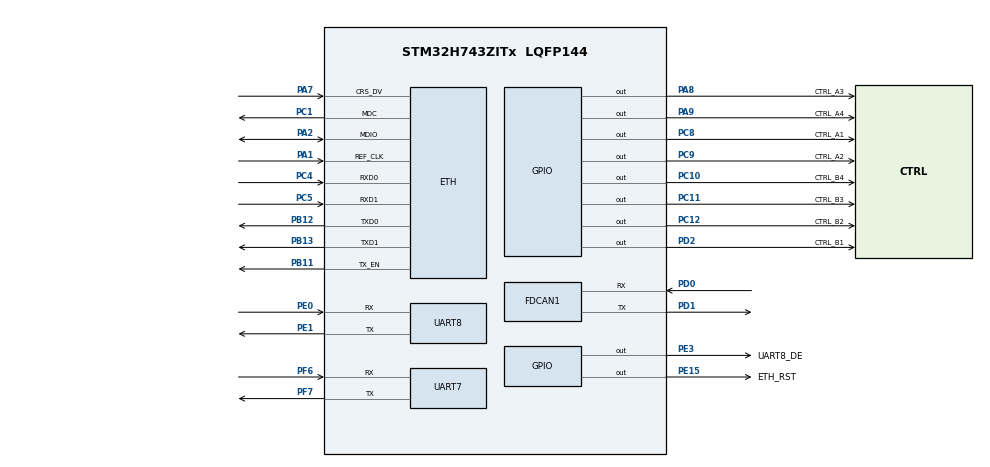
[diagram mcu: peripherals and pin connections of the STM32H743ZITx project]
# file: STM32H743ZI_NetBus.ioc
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CORTEX_M7.AccessPermission_S-Cortex_Memory_Protection_Unit_Region1_Settings_S=MPU_REGION_FULL_ACCESS
CORTEX_M7.AccessPermission_Spec=MPU_REGION_FULL_ACCESS
CORTEX_M7.BaseAddress_S-Cortex_Memory_Protection_Unit_Region1_Settings_S=0x30044000
CORTEX_M7.BaseAddress_Spec=0x30040000
CORTEX_M7.CPU_DCache=Enabled
CORTEX_M7.CPU_ICache=Enabled
CORTEX_M7.DisableExec_Spec=MPU_INSTRUCTION_ACCESS_ENABLE
CORTEX_M7.Enable_S-Cortex_Memory_Protection_Unit_Region1_Settings_S=MPU_REGION_ENABLE
CORTEX_M7.IsBufferable_Spec=MPU_ACCESS_BUFFERABLE
CORTEX_M7.IsCacheable_S-Cortex_Memory_Protection_Unit_Region1_Settings_S=MPU_ACCESS_CACHEABLE
CORTEX_M7.IsShareable_Spec=MPU_ACCESS_NOT_SHAREABLE
CORTEX_M7.Size_S-Cortex_Memory_Protection_Unit_Region1_Settings_S=MPU_REGION_SIZE_16KB
CORTEX_M7.Size_Spec=MPU_REGION_SIZE_256B
CORTEX_M7.SubRegionDisable_Spec=0x00
CORTEX_M7.default_mode_Activation=1
Dma.Request0=UART7_RX
Dma.Request1=UART7_TX
Dma.Request2=UART8_RX
Dma.Request3=UART8_TX
Dma.UART7_RX.0.Direction=DMA_PERIPH_TO_MEMORY
Dma.UART7_RX.0.EventEnable=DISABLE
Dma.UART7_RX.0.FIFOMode=DMA_FIFOMODE_DISABLE
Dma.UART7_RX.0.Instance=DMA1_Stream0
Dma.UART7_RX.0.MemDataAlignment=DMA_MDATAALIGN_BYTE
Dma.UART7_RX.0.MemInc=DMA_MINC_ENABLE
Dma.UART7_RX.0.Mode=DMA_CIRCULAR
Dma.UART7_RX.0.PeriphDataAlignment=DMA_PDATAALIGN_BYTE
Dma.UART7_RX.0.PeriphInc=DMA_PINC_DISABLE
Dma.UART7_RX.0.Polarity=HAL_DMAMUX_REQ_GEN_RISING
Dma.UART7_RX.0.Priority=DMA_PRIORITY_MEDIUM
Dma.UART7_RX.0.RequestNumber=1
Dma.UART7_RX.0.SignalID=NONE
Dma.UART7_RX.0.SyncEnable=DISABLE
Dma.UART7_RX.0.SyncPolarity=HAL_DMAMUX_SYNC_NO_EVENT
Dma.UART7_RX.0.SyncRequestNumber=1
Dma.UART7_RX.0.SyncSignalID=NONE
Dma.UART7_TX.1.Direction=DMA_MEMORY_TO_PERIPH
Dma.UART7_TX.1.EventEnable=DISABLE
Dma.UART7_TX.1.FIFOMode=DMA_FIFOMODE_DISABLE
Dma.UART7_TX.1.Instance=DMA1_Stream1
Dma.UART7_TX.1.MemDataAlignment=DMA_MDATAALIGN_BYTE
Dma.UART7_TX.1.MemInc=DMA_MINC_ENABLE
Dma.UART7_TX.1.Mode=DMA_NORMAL
Dma.UART7_TX.1.PeriphDataAlignment=DMA_PDATAALIGN_BYTE
Dma.UART7_TX.1.PeriphInc=DMA_PINC_DISABLE
Dma.UART7_TX.1.Polarity=HAL_DMAMUX_REQ_GEN_RISING
Dma.UART7_TX.1.Priority=DMA_PRIORITY_LOW
Dma.UART7_TX.1.RequestNumber=1
Dma.UART7_TX.1.SignalID=NONE
Dma.UART7_TX.1.SyncEnable=DISABLE
Dma.UART7_TX.1.SyncPolarity=HAL_DMAMUX_SYNC_NO_EVENT
Dma.UART7_TX.1.SyncRequestNumber=1
Dma.UART7_TX.1.SyncSignalID=NONE
Dma.UART8_RX.2.Direction=DMA_PERIPH_TO_MEMORY
Dma.UART8_RX.2.EventEnable=DISABLE
Dma.UART8_RX.2.FIFOMode=DMA_FIFOMODE_DISABLE
Dma.UART8_RX.2.Instance=DMA1_Stream2
Dma.UART8_RX.2.MemDataAlignment=DMA_MDATAALIGN_BYTE
Dma.UART8_RX.2.MemInc=DMA_MINC_ENABLE
Dma.UART8_RX.2.Mode=DMA_CIRCULAR
Dma.UART8_RX.2.PeriphDataAlignment=DMA_PDATAALIGN_BYTE
Dma.UART8_RX.2.PeriphInc=DMA_PINC_DISABLE
Dma.UART8_RX.2.Polarity=HAL_DMAMUX_REQ_GEN_RISING
Dma.UART8_RX.2.Priority=DMA_PRIORITY_HIGH
Dma.UART8_RX.2.RequestNumber=1
Dma.UART8_RX.2.SignalID=NONE
Dma.UART8_RX.2.SyncEnable=DISABLE
Dma.UART8_RX.2.SyncPolarity=HAL_DMAMUX_SYNC_NO_EVENT
Dma.UART8_RX.2.SyncRequestNumber=1
Dma.UART8_RX.2.SyncSignalID=NONE
Dma.UART8_TX.3.Direction=DMA_MEMORY_TO_PERIPH
Dma.UART8_TX.3.EventEnable=DISABLE
Dma.UART8_TX.3.FIFOMode=DMA_FIFOMODE_DISABLE
Dma.UART8_TX.3.Instance=DMA1_Stream3
Dma.UART8_TX.3.MemDataAlignment=DMA_MDATAALIGN_BYTE
Dma.UART8_TX.3.MemInc=DMA_MINC_ENABLE
Dma.UART8_TX.3.Mode=DMA_NORMAL
Dma.UART8_TX.3.PeriphDataAlignment=DMA_PDATAALIGN_BYTE
Dma.UART8_TX.3.PeriphInc=DMA_PINC_DISABLE
Dma.UART8_TX.3.Polarity=HAL_DMAMUX_REQ_GEN_RISING
Dma.UART8_TX.3.Priority=DMA_PRIORITY_MEDIUM
Dma.UART8_TX.3.RequestNumber=1
Dma.UART8_TX.3.SignalID=NONE
Dma.UART8_TX.3.SyncEnable=DISABLE
Dma.UART8_TX.3.SyncPolarity=HAL_DMAMUX_SYNC_NO_EVENT
Dma.UART8_TX.3.SyncRequestNumber=1
Dma.UART8_TX.3.SyncSignalID=NONE
ETH.MediaInterface=HAL_ETH_RMII_MODE
ETH.RxBuffLen=1528
ETH.RxBufferAddress=0x30040200
ETH.RxDescAddress=0x30040000
ETH.TxDescAddress=0x30040060
FDCAN1.AutoRetransmission=ENABLE
FDCAN1.CalculateBaudRateNominal=1000000
FDCAN1.CalculateTimeBitNominal=1000
FDCAN1.CalculateTimeQuantumNominal=15.625
FDCAN1.DataTimeSeg1=23
FDCAN1.ExtFiltersNbr=4
FDCAN1.FrameFormat=FDCAN_FRAME_FD_BRS
FDCAN1.NominalPrescaler=1
FDCAN1.NominalSyncJumpWidth=16
FDCAN1.NominalTimeSeg1=47
FDCAN1.NominalTimeSeg2=16
FDCAN1.RxBufferSize=FDCAN_DATA_BYTES_64
FDCAN1.RxBuffersNbr=2
FDCAN1.RxFifo0ElmtSize=FDCAN_DATA_BYTES_64
FDCAN1.RxFifo0ElmtsNbr=8
FDCAN1.RxFifo1ElmtSize=FDCAN_DATA_BYTES_64
FDCAN1.RxFifo1ElmtsNbr=8
FDCAN1.StdFiltersNbr=4
FDCAN1.TxBuffersNbr=8
FDCAN1.TxElmtSize=FDCAN_DATA_BYTES_64
FDCAN1.TxEventsNbr=8
FDCAN1.TxFifoQueueElmtsNbr=8
FREERTOS.Mutexes01=SCPI_Mutex,Dynamic,NULL,Available;Modbus_Mutex,Dynamic,NULL,Available
FREERTOS.Tasks01=defaultTask,24,512,StartDefaultTask,As weak,NULL,Dynamic,NULL,NULL;ETH_Task,24,4096,StartETHTask,As weak,NULL,Dynamic,NULL,NULL;Modbus_Task,8,512,StartModbusTask,As weak,NULL,Dynamic,NULL,NULL;Can_Task,8,512,StartCanTask,As weak,NULL,Dynamic,NULL,NULL;SCPI_Task,8,1024,StartSCPITask,As weak,NULL,Dynamic,NULL,NULL
FREERTOS.configMINIMAL_STACK_SIZE=256
FREERTOS.configTOTAL_HEAP_SIZE=40960
FREERTOS.configUSE_NEWLIB_REENTRANT=1
LWIP.BSP.number=1
LWIP.GATEWAY_ADDRESS=192.168.001.001
LWIP.HTTPD_USE_CUSTOM_FSDATA=1
LWIP.IP_ADDRESS=192.168.001.010
LWIP.LWIP_DHCP=0
LWIP.LWIP_HTTPD=1
LWIP.LWIP_NETIF_STATUS_CALLBACK=1
LWIP.LWIP_RAM_HEAP_POINTER=0x30044000
LWIP.MEMP_MEM_MALLOC=1
LWIP.MEM_SIZE=14336
LWIP.NETMASK_ADDRESS=255.255.255.000
LWIP.TCPIP_THREAD_PRIO=25
LWIP.Version=v2.2.1_Cube
LWIP0.BSP.STBoard=false
LWIP0.BSP.api=BSP_COMPONENT_DRIVER
LWIP0.BSP.component=LAN8742
LWIP0.BSP.instance=LAN8742
LWIP0.BSP.name=Driver_PHY
LWIP0.BSP.semaphore=S_LAN8742
LWIP0.BSP.solution=LAN8742
Mcu.Family=STM32H7
Mcu.Name=STM32H743ZITx
Mcu.Package=LQFP144
NVIC.DMA1_Stream0_IRQn=true\:8\:0\:true\:false\:true\:true\:false\:true\:true
NVIC.DMA1_Stream1_IRQn=true\:9\:0\:true\:false\:true\:true\:false\:true\:true
NVIC.DMA1_Stream2_IRQn=true\:9\:0\:true\:false\:true\:true\:false\:true\:true
NVIC.DMA1_Stream3_IRQn=true\:10\:0\:true\:false\:true\:true\:false\:true\:true
NVIC.ETH_IRQn=true\:6\:0\:true\:false\:true\:true\:true\:true\:true
NVIC.ETH_WKUP_IRQn=true\:6\:0\:true\:false\:true\:true\:true\:true\:true
NVIC.FDCAN1_IT0_IRQn=true\:7\:0\:true\:false\:true\:true\:true\:true\:true
NVIC.FDCAN1_IT1_IRQn=true\:7\:0\:true\:false\:true\:true\:true\:true\:true
NVIC.PriorityGroup=NVIC_PRIORITYGROUP_4
NVIC.TIM1_UP_IRQn=true\:15\:0\:false\:false\:true\:false\:false\:true\:true
NVIC.TimeBase=TIM1_UP_IRQn
NVIC.TimeBaseIP=TIM1
NVIC.UART7_IRQn=true\:9\:0\:true\:false\:true\:true\:true\:true\:true
NVIC.UART8_IRQn=true\:8\:0\:true\:false\:true\:true\:true\:true\:true
PA1.GPIO_Speed_Default_HIGH=GPIO_SPEED_FREQ_VERY_HIGH
PA1.Mode=RMII
PA1.Signal=ETH_REF_CLK
PA13\ (JTMS/SWDIO).Mode=Serial_Wire
PA13\ (JTMS/SWDIO).Signal=DEBUG_JTMS-SWDIO
PA14\ (JTCK/SWCLK).Mode=Serial_Wire
PA14\ (JTCK/SWCLK).Signal=DEBUG_JTCK-SWCLK
PA2.GPIO_Speed_Default_HIGH=GPIO_SPEED_FREQ_VERY_HIGH
PA2.Mode=RMII
PA2.Signal=ETH_MDIO
PA7.GPIO_Speed_Default_HIGH=GPIO_SPEED_FREQ_VERY_HIGH
PA7.Mode=RMII
PA7.Signal=ETH_CRS_DV
PA8.GPIO_Label=CTRL_A3
PA8.Signal=GPIO_Output
PA9.GPIO_Label=CTRL_A4
PA9.Signal=GPIO_Output
PB11.GPIO_Speed_Default_HIGH=GPIO_SPEED_FREQ_VERY_HIGH
PB11.Mode=RMII
PB11.Signal=ETH_TX_EN
PB12.GPIO_Speed_Default_HIGH=GPIO_SPEED_FREQ_VERY_HIGH
PB12.Mode=RMII
PB12.Signal=ETH_TXD0
PB13.GPIO_Speed_Default_HIGH=GPIO_SPEED_FREQ_VERY_HIGH
PB13.Mode=RMII
PB13.Signal=ETH_TXD1
PC1.GPIO_Speed_Default_HIGH=GPIO_SPEED_FREQ_VERY_HIGH
PC1.Mode=RMII
PC1.Signal=ETH_MDC
PC10.GPIO_Label=CTRL_B4
PC10.Signal=GPIO_Output
PC11.GPIO_Label=CTRL_B3
PC11.Signal=GPIO_Output
PC12.GPIO_Label=CTRL_B2
PC12.Signal=GPIO_Output
PC4.GPIO_Speed_Default_HIGH=GPIO_SPEED_FREQ_VERY_HIGH
PC4.Mode=RMII
PC4.Signal=ETH_RXD0
PC5.GPIO_Speed_Default_HIGH=GPIO_SPEED_FREQ_VERY_HIGH
PC5.Mode=RMII
PC5.Signal=ETH_RXD1
PC8.GPIO_Label=CTRL_A1
PC8.Signal=GPIO_Output
PC9.GPIO_Label=CTRL_A2
PC9.Signal=GPIO_Output
PD0.Mode=FDCAN_Activate
PD0.Signal=FDCAN1_RX
PD1.Mode=FDCAN_Activate
PD1.Signal=FDCAN1_TX
PD2.GPIO_Label=CTRL_B1
PD2.Signal=GPIO_Output
PE0.Mode=Asynchronous
PE0.Signal=UART8_RX
PE1.Mode=Asynchronous
PE1.Signal=UART8_TX
PE15.GPIO_Label=ETH_RST
PE15.PinState=GPIO_PIN_SET
PE15.Signal=GPIO_Output
PE3.GPIO_Label=UART8_DE
PE3.Signal=GPIO_Output
PF6.Mode=Asynchronous
PF6.Signal=UART7_RX
PF7.Mode=Asynchronous
PF7.Signal=UART7_TX
PH0-OSC_IN\ (PH0).Mode=HSE-External-Oscillator
PH0-OSC_IN\ (PH0).Signal=RCC_OSC_IN
PH1-OSC_OUT\ (PH1).Mode=HSE-External-Oscillator
PH1-OSC_OUT\ (PH1).Signal=RCC_OSC_OUT
ProjectManager.HeapSize=0x2000
ProjectManager.StackSize=0x1000
ProjectManager.TargetToolchain=STM32CubeIDE
RCC.ADCFreq_Value=50390625
RCC.APB1Freq_Value=120000000
RCC.APB2Freq_Value=120000000
RCC.APB3Freq_Value=120000000
RCC.APB4Freq_Value=120000000
RCC.CortexFreq_Value=480000000
RCC.D1PPRE=RCC_APB3_DIV2
RCC.D2PPRE1=RCC_APB1_DIV2
RCC.D2PPRE2=RCC_APB2_DIV2
RCC.D3PPRE=RCC_APB4_DIV2
RCC.DIVM1=5
RCC.DIVN1=192
RCC.DIVQ1=15
RCC.HCLKFreq_Value=240000000
RCC.HPRE=RCC_HCLK_DIV2
RCC.PLL2FRACN=0
RCC.PLL3FRACN=0
RCC.PLLFRACN=0
RCC.PLLSourceVirtual=RCC_PLLSOURCE_HSE
RCC.SYSCLKFreq_VALUE=480000000
RCC.SYSCLKSource=RCC_SYSCLKSOURCE_PLLCLK
RCC.USBFreq_Value=64000000
VP_FREERTOS_VS_CMSIS_V2.Mode=CMSIS_V2
VP_LWIP_VS_Enabled.Mode=Enabled
VP_MEMORYMAP_VS_MEMORYMAP.Mode=CurAppReg
VP_SYS_VS_tim1.Mode=TIM1
board=custom

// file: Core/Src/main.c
/* USER CODE BEGIN Header */
/**
  ******************************************************************************
  * @file           : main.c
  * @brief          : Main program body
  ******************************************************************************
  * @attention
  *
  * Copyright (c) 2026 STMicroelectronics.
  * All rights reserved.
  *
  * This software is licensed under terms that can be found in the LICENSE file
  * in the root directory of this software component.
  * If no LICENSE file comes with this software, it is provided AS-IS.
  *
  ******************************************************************************
  */
/* USER CODE END Header */
#include "main.h"
#include "FreeRTOS.h"
#include "cmsis_os2.h"
#include "dma.h"
#include "fdcan.h"
#include "lwip.h"
#include "usart.h"
#include "gpio.h"

/* USER CODE BEGIN Includes */
#include "app_task.h"
/* USER CODE END Includes */

void SystemClock_Config(void);
static void MPU_Config(void);
void MX_FREERTOS_Init(void);

int main(void)
{

  /* MPU Configuration--------------------------------------------------------*/
  MPU_Config();

  /* Enable the CPU Cache */

  /* Enable I-Cache---------------------------------------------------------*/
  SCB_EnableICache();

  /* Enable D-Cache---------------------------------------------------------*/
  SCB_EnableDCache();

  /* MCU Configuration--------------------------------------------------------*/

  /* Reset of all peripherals, Initializes the Flash interface and the Systick. */
  HAL_Init();

  /* Configure the system clock */
  SystemClock_Config();

  /* Initialize all configured peripherals */
  MX_GPIO_Init();
  MX_DMA_Init();
  MX_FDCAN1_Init();
  MX_UART7_Init();
  MX_UART8_Init();
  /* USER CODE BEGIN 2 */
  /* Initialize all application modules -- registers and initializes built-in tasks */
  if (App_Init() != APP_OK)
  {
      Error_Handler();
  }
  /* USER CODE END 2 */

  /* Init scheduler */
  osKernelInitialize();  /* Call init function for freertos objects (in cmsis_os2.c) */
  MX_FREERTOS_Init();

  /* Start scheduler */
  osKernelStart();

  /* We should never get here as control is now taken by the scheduler */

  /* Infinite loop */
  /* USER CODE BEGIN WHILE */
  while (1)
  {
    osDelay(1000);
  }
    /* USER CODE END WHILE */

}

void SystemClock_Config(void)
{
  RCC_OscInitTypeDef RCC_OscInitStruct = {0};
  RCC_ClkInitTypeDef RCC_ClkInitStruct = {0};

  /** Supply configuration update enable
  */
  HAL_PWREx_ConfigSupply(PWR_LDO_SUPPLY);

  /** Configure the main internal regulator output voltage
  */
  __HAL_PWR_VOLTAGESCALING_CONFIG(PWR_REGULATOR_VOLTAGE_SCALE0);

  while(!__HAL_PWR_GET_FLAG(PWR_FLAG_VOSRDY)) {}

  /** Initializes the RCC Oscillators according to the specified parameters
  * in the RCC_OscInitTypeDef structure.
  */
  RCC_OscInitStruct.OscillatorType = RCC_OSCILLATORTYPE_HSE;
  RCC_OscInitStruct.HSEState = RCC_HSE_ON;
  RCC_OscInitStruct.PLL.PLLState = RCC_PLL_ON;
  RCC_OscInitStruct.PLL.PLLSource = RCC_PLLSOURCE_HSE;
  RCC_OscInitStruct.PLL.PLLM = 5;
  RCC_OscInitStruct.PLL.PLLN = 192;
  RCC_OscInitStruct.PLL.PLLP = 2;
  RCC_OscInitStruct.PLL.PLLQ = 15;
  RCC_OscInitStruct.PLL.PLLR = 2;
  RCC_OscInitStruct.PLL.PLLRGE = RCC_PLL1VCIRANGE_2;
  RCC_OscInitStruct.PLL.PLLVCOSEL = RCC_PLL1VCOWIDE;
  RCC_OscInitStruct.PLL.PLLFRACN = 0;
  if (HAL_RCC_OscConfig(&RCC_OscInitStruct) != HAL_OK)
  {
    Error_Handler();
  }

  /** Initializes the CPU, AHB and APB buses clocks
  */
  RCC_ClkInitStruct.ClockType = RCC_CLOCKTYPE_HCLK|RCC_CLOCKTYPE_SYSCLK
                              |RCC_CLOCKTYPE_PCLK1|RCC_CLOCKTYPE_PCLK2
                              |RCC_CLOCKTYPE_D3PCLK1|RCC_CLOCKTYPE_D1PCLK1;
  RCC_ClkInitStruct.SYSCLKSource = RCC_SYSCLKSOURCE_PLLCLK;
  RCC_ClkInitStruct.SYSCLKDivider = RCC_SYSCLK_DIV1;
  RCC_ClkInitStruct.AHBCLKDivider = RCC_HCLK_DIV2;
  RCC_ClkInitStruct.APB3CLKDivider = RCC_APB3_DIV2;
  RCC_ClkInitStruct.APB1CLKDivider = RCC_APB1_DIV2;
  RCC_ClkInitStruct.APB2CLKDivider = RCC_APB2_DIV2;
  RCC_ClkInitStruct.APB4CLKDivider = RCC_APB4_DIV2;

  if (HAL_RCC_ClockConfig(&RCC_ClkInitStruct, FLASH_LATENCY_4) != HAL_OK)
  {
    Error_Handler();
  }
}

 /* MPU Configuration */

void MPU_Config(void)
{
  MPU_Region_InitTypeDef MPU_InitStruct = {0};

  /* Disables the MPU */
  HAL_MPU_Disable();

  /** Initializes and configures the Region and the memory to be protected
  */
  MPU_InitStruct.Enable = MPU_REGION_ENABLE;
  MPU_InitStruct.Number = MPU_REGION_NUMBER0;
  MPU_InitStruct.BaseAddress = 0x30040000;
  MPU_InitStruct.Size = MPU_REGION_SIZE_256B;
  MPU_InitStruct.SubRegionDisable = 0x00;
  MPU_InitStruct.TypeExtField = MPU_TEX_LEVEL0;
  MPU_InitStruct.AccessPermission = MPU_REGION_FULL_ACCESS;
  MPU_InitStruct.DisableExec = MPU_INSTRUCTION_ACCESS_ENABLE;
  MPU_InitStruct.IsShareable = MPU_ACCESS_NOT_SHAREABLE;
  MPU_InitStruct.IsCacheable = MPU_ACCESS_NOT_CACHEABLE;
  MPU_InitStruct.IsBufferable = MPU_ACCESS_BUFFERABLE;

  HAL_MPU_ConfigRegion(&MPU_InitStruct);

  /** Initializes and configures the Region and the memory to be protected
  */
  MPU_InitStruct.Number = MPU_REGION_NUMBER1;
  MPU_InitStruct.BaseAddress = 0x30044000;
  MPU_InitStruct.Size = MPU_REGION_SIZE_16KB;
  MPU_InitStruct.SubRegionDisable = 0x0;
  MPU_InitStruct.IsCacheable = MPU_ACCESS_CACHEABLE;
  MPU_InitStruct.IsBufferable = MPU_ACCESS_NOT_BUFFERABLE;

  HAL_MPU_ConfigRegion(&MPU_InitStruct);
  /* Enables the MPU */
  HAL_MPU_Enable(MPU_PRIVILEGED_DEFAULT);

}

void HAL_TIM_PeriodElapsedCallback(TIM_HandleTypeDef *htim)
{
  if (htim->Instance == TIM1)
  {
    HAL_IncTick();
  }
}

void Error_Handler(void)
{
  __disable_irq();
  while (1)
  {
  }
}

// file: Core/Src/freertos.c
/* USER CODE BEGIN Header */
/**
  ******************************************************************************
  * File Name          : freertos.c
  * Description        : Code for freertos applications
  ******************************************************************************
  * @attention
  *
  * Copyright (c) 2026 STMicroelectronics.
  * All rights reserved.
  *
  * This software is licensed under terms that can be found in the LICENSE file
  * in the root directory of this software component.
  * If no LICENSE file comes with this software, it is provided AS-IS.
  *
  ******************************************************************************
  */
/* USER CODE END Header */

#include "FreeRTOS.h"
#include "task.h"
#include "main.h"
#include "FreeRTOS.h"
#include "cmsis_os2.h"

/* Definitions for defaultTask */
osThreadId_t defaultTaskHandle;
const osThreadAttr_t defaultTask_attributes = {
  .name = "defaultTask",
  .stack_size = 512 * 4,
  .priority = (osPriority_t) osPriorityNormal,
};
/* Definitions for ETH_Task */
osThreadId_t ETH_TaskHandle;
const osThreadAttr_t ETH_Task_attributes = {
  .name = "ETH_Task",
  .stack_size = 4096 * 4,
  .priority = (osPriority_t) osPriorityNormal,
};
/* Definitions for Modbus_Task */
osThreadId_t Modbus_TaskHandle;
const osThreadAttr_t Modbus_Task_attributes = {
  .name = "Modbus_Task",
  .stack_size = 512 * 4,
  .priority = (osPriority_t) osPriorityLow,
};
/* Definitions for Can_Task */
osThreadId_t Can_TaskHandle;
const osThreadAttr_t Can_Task_attributes = {
  .name = "Can_Task",
  .stack_size = 512 * 4,
  .priority = (osPriority_t) osPriorityLow,
};
/* Definitions for SCPI_Task */
osThreadId_t SCPI_TaskHandle;
const osThreadAttr_t SCPI_Task_attributes = {
  .name = "SCPI_Task",
  .stack_size = 1024 * 4,
  .priority = (osPriority_t) osPriorityLow,
};
/* Definitions for SCPI_Mutex */
osMutexId_t SCPI_MutexHandle;
const osMutexAttr_t SCPI_Mutex_attributes = {
  .name = "SCPI_Mutex"
};
/* Definitions for Modbus_Mutex */
osMutexId_t Modbus_MutexHandle;
const osMutexAttr_t Modbus_Mutex_attributes = {
  .name = "Modbus_Mutex"
};

void StartDefaultTask(void *argument);
void StartETHTask(void *argument);
void StartModbusTask(void *argument);
void StartCanTask(void *argument);
void StartSCPITask(void *argument);

extern void MX_LWIP_Init(void);
void MX_FREERTOS_Init(void); /* (MISRA C 2004 rule 8.1) */

void MX_FREERTOS_Init(void) {
  /* Create the mutex(es) */
  /* creation of SCPI_Mutex */
  SCPI_MutexHandle = osMutexNew(&SCPI_Mutex_attributes);

  /* creation of Modbus_Mutex */
  Modbus_MutexHandle = osMutexNew(&Modbus_Mutex_attributes);

  /* Create the thread(s) */
  /* creation of defaultTask */
  defaultTaskHandle = osThreadNew(StartDefaultTask, NULL, &defaultTask_attributes);

  /* creation of ETH_Task */
  ETH_TaskHandle = osThreadNew(StartETHTask, NULL, &ETH_Task_attributes);

  /* creation of Modbus_Task */
  Modbus_TaskHandle = osThreadNew(StartModbusTask, NULL, &Modbus_Task_attributes);

  /* creation of Can_Task */
  Can_TaskHandle = osThreadNew(StartCanTask, NULL, &Can_Task_attributes);

  /* creation of SCPI_Task */
  SCPI_TaskHandle = osThreadNew(StartSCPITask, NULL, &SCPI_Task_attributes);

}

__weak void StartDefaultTask(void *argument)
{
  /* init code for LWIP */
  MX_LWIP_Init();
  for(;;)
  {
    osDelay(1);
  }
}

__weak void StartETHTask(void *argument)
{
  for(;;)
  {
    osDelay(1);
  }
}

__weak void StartModbusTask(void *argument)
{
  for(;;)
  {
    osDelay(1);
  }
}

__weak void StartCanTask(void *argument)
{
  for(;;)
  {
    osDelay(1);
  }
}

__weak void StartSCPITask(void *argument)
{
  for(;;)
  {
    osDelay(1);
  }
}
